# ATSAML10E16A register map
Vendor: Microchip Technology; Series: SAML10; File version: 0
Microchip ATSAML10E16A Microcontroller
CPU: CM23 r0p0, selectable endian, MPU, no FPU, 2 interrupt priority bits
Registers are 32-bit, read-write, reset 0x0 unless marked. A register's access mark holds for its fields unless they carry their own. Offsets are from the block's base; lines under a group give offsets from that group; [hi:lo] are bit positions; {n}, {i} and the like mark numbered series; 'fields as' and 'values as' point back to an identical list; <NAME> marks a mode.

## Memory map
0x40000000 PAC size 0x60 — Peripheral Access Controller
0x40000400 PM size 0xA — Power Manager
0x40000800 MCLK size 0x20 — Main Clock
0x40000C00 RSTC size 0x1 — Reset Controller
0x40001000 OSCCTRL size 0x41 — Oscillators Control
0x40001400 OSC32KCTRL size 0x20 — 32k Oscillators Control
0x40001800 SUPC size 0x30 — Supply Controller
0x40001C00 GCLK size 0x104 — Generic Clock Generator
0x40002000 WDT size 0xD — Watchdog Timer
0x40002400 RTC size 0x70 — Real-Time Counter
0x40002800 EIC size 0x44 — External Interrupt Controller
0x40002C00 FREQM size 0x14 — Frequency Meter
0x40003000 PORT size 0x80 — Port Module
0x40003400 AC size 0x24 — Analog Comparators
0x41000000 IDAU — Implementation Defined Attribution Unit
0x41002000 DSU size 0x2000 — Device Service Unit
0x41002100 DSU_EXT size 0x2000
0x41004000 NVMCTRL size 0x48 — Non-Volatile Memory Controller
0x41006000 DMAC size 0x50 — Direct Memory Access Controller
0x42000000 EVSYS size 0x1F4 — Event System Interface
0x42000400 SERCOM0 size 0x31 — Serial Communication Interface
0x42000800 SERCOM1 size 0x31
0x42000C00 SERCOM2 size 0x31
0x42001000 TC0 size 0x38 — Basic Timer Counter
0x42001400 TC1 size 0x38
0x42001800 TC2 size 0x38
0x42001C00 ADC size 0x2E — Analog Digital Converter
0x42002000 DAC size 0x15 — Digital Analog Converter
0x42002400 PTC — Peripheral Touch Controller
0x42002800 TRNG size 0x24 — True Random Generator
0x42002C00 CCL size 0x10 — Configurable Custom Logic
0x42003000 OPAMP size 0x11 — Operational Amplifier
0x42003400 TRAM size 0x290 — TrustRAM
0x60000000 PORT_IOBUS size 0x80
0xE0001000 DWT size 0x1000 — Data Watchpoint and Trace
0xE0002000 FPB size 0x1000 — Flash Patch and Breakpoint
0xE000E000 ICB size 0xC — Implementation Control Block
0xE000E010 SysTick size 0x10 — SysTick Timer
0xE000E100 NVIC size 0x348 — Nested Vectored Interrupt Controller
0xE000ED00 SCB size 0x88 — System Control Block
0xE000ED90 MPU size 0x38 — Memory Protection Unit
0xE000EDF0 CoreDebug size 0x1C — Debug Control Block
0xE000EFB0 DIB size 0x50 — Debug Identification Block

## Interrupts
1 WDT
2 RTC
3 EIC_EXTINT_0 (EIC)
4 EIC_EXTINT_1 (EIC)
5 EIC_EXTINT_2 (EIC)
6 EIC_EXTINT_3 (EIC)
7 EIC_OTHER (EIC)
8 FREQM
9 NVMCTRL
10 PORT
11 DMAC_0 (DMAC)
12 DMAC_1 (DMAC)
13 DMAC_2 (DMAC)
14 DMAC_3 (DMAC)
15 DMAC_OTHER (DMAC)
16 EVSYS_0 (EVSYS)
17 EVSYS_1 (EVSYS)
18 EVSYS_2 (EVSYS)
19 EVSYS_3 (EVSYS)
20 EVSYS_NSCHK (EVSYS)
21 PAC
22 SERCOM0_0 (SERCOM0)
23 SERCOM0_1 (SERCOM0)
24 SERCOM0_2 (SERCOM0)
25 SERCOM0_OTHER (SERCOM0)
26 SERCOM1_0 (SERCOM1)
27 SERCOM1_1 (SERCOM1)
28 SERCOM1_2 (SERCOM1)
29 SERCOM1_OTHER (SERCOM1)
30 SERCOM2_0 (SERCOM2)
31 SERCOM2_1 (SERCOM2)
32 SERCOM2_2 (SERCOM2)
33 SERCOM2_OTHER (SERCOM2)
34 TC0
35 TC1
36 TC2
37 ADC_OTHER (ADC)
38 ADC_RESRDY (ADC)
39 AC
40 DAC_UNDERRUN_A (DAC)
41 DAC_EMPTY (DAC)
42 PTC
43 TRNG
44 TRAM

## CCL — Configurable Custom Logic
Base 0x42002C00; register names take the prefix CCL_
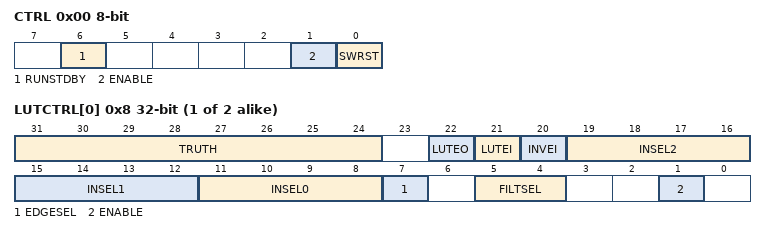
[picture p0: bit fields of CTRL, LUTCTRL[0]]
0x00 CTRL 8-bit — Control
  [6] RUNSTDBY — Run in Standby
    0=DISABLE (Generic clock is not required in standby sleep mode); 1=ENABLE (Generic clock is required in standby sleep mode)
  [1] ENABLE
    0=DISABLE (The peripheral is disabled); 1=ENABLE (The peripheral is enabled)
  [0] SWRST — Software Reset
    0=DISABLE (The peripheral is not reset); 1=ENABLE (The peripheral is reset)
{0x4+i} SEQCTRL[{i}] (i=0..0) 8-bit — SEQ Control x
  [3:0] SEQSEL — Sequential Selection
    0=DISABLE (Sequential logic is disabled); 1=DFF (D flip flop); 2=JK (JK flip flop); 3=LATCH (D latch); 4=RS (RS latch)
{0x8+4i} LUTCTRL[{i}] (i=0..1) — LUT Control x
  [31:24] TRUTH — Truth Value
  [22] LUTEO — LUT Event Output Enable
    0=DISABLE (LUT event output is disabled); 1=ENABLE (LUT event output is enabled)
  [21] LUTEI — LUT Event Input Enable
    0=DISABLE (LUT incoming event is disabled); 1=ENABLE (LUT incoming event is enabled)
  [20] INVEI — Inverted Event Input Enable
    0=NORMAL (Incoming event is not inverted); 1=INVERTED (Incoming event is inverted)
  [19:16] INSEL2 — Input Selection 2
    0=MASK (Masked input); 1=FEEDBACK (Feedback input source); 2=LINK (Linked LUT input source); 3=EVENT (Event input source); 4=IO (I/O pin input source); 5=AC (AC input source); 6=TC (TC input source); 7=ALTTC (Alternate TC input source); 9=SERCOM (SERCOM input source); 11=ASYNCEVENT (Asynchronous event input source)
  [15:12] INSEL1 — Input Selection 1
    values as INSEL2
  [11:8] INSEL0 — Input Selection 0
    values as INSEL2
  [7] EDGESEL — Edge Selection
    0=DISABLE (Edge detector is disabled); 1=ENABLE (Edge detector is enabled)
  [5:4] FILTSEL — Filter Selection
    0=DISABLE (Filter disabled); 1=SYNCH (Synchronizer enabled); 2=FILTER (Filter enabled)
  [1] ENABLE — LUT Enable
    0=DISABLE (LUT block is disabled); 1=ENABLE (LUT block is enabled)

## Notices in the file
Copyright (c) 2017 Microchip Technology Inc.
SPDX-License-Identifier: Apache-2.0
Licensed under the Apache License, Version 2.0 (the "License");
you may not use this file except in compliance with the License.
You may obtain a copy of the License at
http://www.apache.org/licenses/LICENSE-2.0
Unless required by applicable law or agreed to in writing, software
distributed under the License is distributed on an "AS IS" BASIS,
WITHOUT WARRANTIES OR CONDITIONS OF ANY KIND, either express or implied.
See the License for the specific language governing permissions and
limitations under the License.
